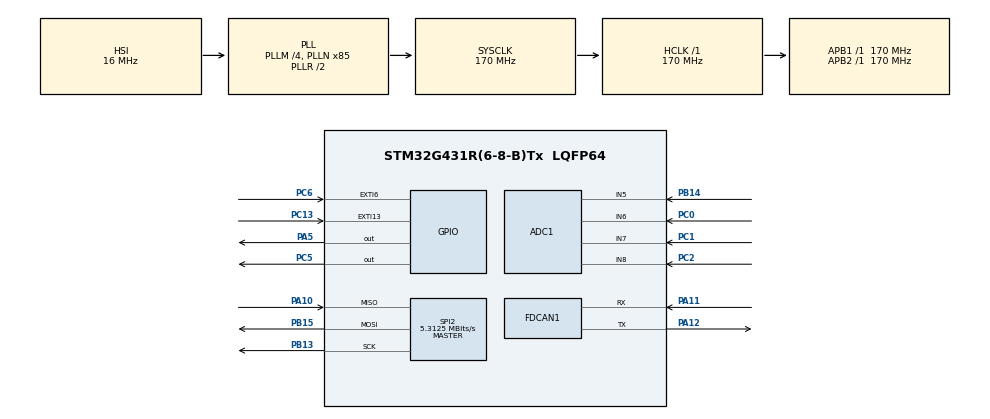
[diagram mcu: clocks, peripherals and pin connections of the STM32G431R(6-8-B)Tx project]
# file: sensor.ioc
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ADC1.Channel-1\#ChannelRegularConversion=ADC_CHANNEL_6
ADC1.Channel-6\#ChannelRegularConversion=ADC_CHANNEL_7
ADC1.Channel-7\#ChannelRegularConversion=ADC_CHANNEL_8
ADC1.Channel-8\#ChannelRegularConversion=ADC_CHANNEL_5
ADC1.ContinuousConvMode=DISABLE
ADC1.DMAContinuousRequests=DISABLE
ADC1.EnableInjectedConversion=DISABLE
ADC1.NbrOfConversion=4
ADC1.NbrOfConversionFlag=1
ADC1.OffsetNumber-1\#ChannelRegularConversion=ADC_OFFSET_NONE
ADC1.OffsetNumber-6\#ChannelRegularConversion=ADC_OFFSET_NONE
ADC1.OffsetNumber-7\#ChannelRegularConversion=ADC_OFFSET_NONE
ADC1.OffsetNumber-8\#ChannelRegularConversion=ADC_OFFSET_NONE
ADC1.Rank-1\#ChannelRegularConversion=1
ADC1.Rank-6\#ChannelRegularConversion=2
ADC1.Rank-7\#ChannelRegularConversion=3
ADC1.Rank-8\#ChannelRegularConversion=4
ADC1.SamplingTime-1\#ChannelRegularConversion=ADC_SAMPLETIME_92CYCLES_5
ADC1.SamplingTime-6\#ChannelRegularConversion=ADC_SAMPLETIME_92CYCLES_5
ADC1.SamplingTime-7\#ChannelRegularConversion=ADC_SAMPLETIME_92CYCLES_5
ADC1.SamplingTime-8\#ChannelRegularConversion=ADC_SAMPLETIME_92CYCLES_5
ADC1.master=1
Dma.ADC1.0.Direction=DMA_PERIPH_TO_MEMORY
Dma.ADC1.0.EventEnable=DISABLE
Dma.ADC1.0.Instance=DMA1_Channel1
Dma.ADC1.0.MemDataAlignment=DMA_MDATAALIGN_HALFWORD
Dma.ADC1.0.MemInc=DMA_MINC_ENABLE
Dma.ADC1.0.Mode=DMA_NORMAL
Dma.ADC1.0.PeriphDataAlignment=DMA_PDATAALIGN_HALFWORD
Dma.ADC1.0.PeriphInc=DMA_PINC_DISABLE
Dma.ADC1.0.Polarity=HAL_DMAMUX_REQ_GEN_RISING
Dma.ADC1.0.Priority=DMA_PRIORITY_LOW
Dma.ADC1.0.RequestNumber=1
Dma.ADC1.0.SignalID=NONE
Dma.ADC1.0.SyncEnable=DISABLE
Dma.ADC1.0.SyncPolarity=HAL_DMAMUX_SYNC_NO_EVENT
Dma.ADC1.0.SyncRequestNumber=1
Dma.ADC1.0.SyncSignalID=NONE
Dma.Request0=ADC1
FDCAN1.CalculateBaudRateNominal=499999
FDCAN1.CalculateTimeBitNominal=2000
FDCAN1.CalculateTimeQuantumNominal=117.64705882352942
FDCAN1.DataPrescaler=2
FDCAN1.DataTimeSeg1=14
FDCAN1.DataTimeSeg2=2
FDCAN1.Mode=FDCAN_MODE_NORMAL
FDCAN1.NominalPrescaler=20
FDCAN1.NominalTimeSeg1=14
FDCAN1.ProtocolException=ENABLE
FDCAN1.StdFiltersNbr=FDCAN_FILTER_COUNT
FDCAN1.TransmitPause=ENABLE
FREERTOS.Tasks01=defaultTask,24,128,StartDefaultTask,As weak,NULL,Dynamic,NULL,NULL;UsTask,40,128,StartUsTask,As weak,NULL,Dynamic,NULL,NULL;AdcTask,25,128,StartAdcTask,As weak,NULL,Dynamic,NULL,NULL;FdCanTask,40,128,StartFdCanTask,As weak,NULL,Dynamic,NULL,NULL
FREERTOS.configENABLE_BACKWARD_COMPATIBILITY=0
FREERTOS.configUSE_NEWLIB_REENTRANT=1
Mcu.Family=STM32G4
Mcu.Name=STM32G431R(6-8-B)Tx
Mcu.Package=LQFP64
NUCLEO-G431RB.BUTTON=1
NUCLEO-G431RB.LD1=true
NUCLEO-G431RB.VCP=true
NVIC.DMA1_Channel1_IRQn=true\:5\:0\:false\:false\:true\:true\:false\:true\:true
NVIC.EXTI15_10_IRQn=true\:5\:0\:false\:false\:true\:true\:false\:true\:true
NVIC.EXTI9_5_IRQn=true\:5\:0\:false\:false\:true\:true\:true\:true\:true
NVIC.FDCAN1_IT0_IRQn=true\:5\:0\:false\:false\:true\:true\:true\:true\:true
NVIC.FDCAN1_IT1_IRQn=true\:5\:0\:false\:false\:true\:true\:true\:true\:true
NVIC.PriorityGroup=NVIC_PRIORITYGROUP_4
NVIC.TIM4_IRQn=true\:5\:0\:false\:false\:true\:true\:true\:true\:true
NVIC.TIM6_DAC_IRQn=true\:15\:0\:false\:false\:true\:false\:false\:true\:true
NVIC.TimeBase=TIM6_DAC_IRQn
NVIC.TimeBaseIP=TIM6
PA10.Mode=Full_Duplex_Master
PA10.Signal=SPI2_MISO
PA11.Mode=FDCAN_Activate
PA11.Signal=FDCAN1_RX
PA12.Mode=FDCAN_Activate
PA12.Signal=FDCAN1_TX
PA13.GPIO_Label=T_SWDIO
PA13.Signal=SYS_JTMS-SWDIO
PA14.GPIO_Label=T_SWCLK
PA14.Signal=SYS_JTCK-SWCLK
PA2.Signal=LPUART1_TX
PA3.Signal=LPUART1_RX
PA5.Signal=GPIO_Output
PB11.Signal=ADC1_IN14
PB12.Signal=ADC1_IN11
PB13.Mode=Full_Duplex_Master
PB13.Signal=SPI2_SCK
PB14.Mode=IN5-Single-Ended
PB14.Signal=ADC1_IN5
PB15.Mode=Full_Duplex_Master
PB15.Signal=SPI2_MOSI
PB3.GPIO_Label=T_SWO
PB3.Signal=SYS_JTDO-SWO
PC0.Mode=IN6-Single-Ended
PC0.Signal=ADC1_IN6
PC1.Mode=IN7-Single-Ended
PC1.Signal=ADC1_IN7
PC13.Signal=GPXTI13
PC14-OSC32_IN.GPIO_Label=RCC_OSC32_OUT
PC14-OSC32_IN.Signal=RCC_OSC32_IN
PC15-OSC32_OUT.GPIO_Label=RCC_OSC32_OUT
PC15-OSC32_OUT.Signal=RCC_OSC32_OUT
PC2.Mode=IN8-Single-Ended
PC2.Signal=ADC1_IN8
PC5.Signal=GPIO_Output
PC6.GPIO_ModeDefaultEXTI=GPIO_MODE_IT_FALLING
PC6.Signal=GPXTI6
PF0-OSC_IN.GPIO_Label=RCC_OSC_IN
PF0-OSC_IN.Signal=RCC_OSC_IN
PF1-OSC_OUT.GPIO_Label=RCC_OSC_OUT
PF1-OSC_OUT.Signal=RCC_OSC_OUT
ProjectManager.HeapSize=0x200
ProjectManager.StackSize=0x400
ProjectManager.TargetToolchain=STM32CubeIDE
RCC.ADC12Freq_Value=170000000
RCC.AHBFreq_Value=170000000
RCC.APB1Freq_Value=170000000
RCC.APB1TimFreq_Value=170000000
RCC.APB2Freq_Value=170000000
RCC.APB2TimFreq_Value=170000000
RCC.CortexFreq_Value=170000000
RCC.EXTERNAL_CLOCK_VALUE=12288000
RCC.HCLKFreq_Value=170000000
RCC.HSE_VALUE=24000000
RCC.HSI48_VALUE=48000000
RCC.HSI_VALUE=16000000
RCC.LSE_VALUE=32768
RCC.PLLM=RCC_PLLM_DIV4
RCC.PLLN=85
RCC.RTCClockSelection=RCC_RTCCLKSOURCE_LSE
RCC.SYSCLKFreq_VALUE=170000000
RCC.SYSCLKSource=RCC_SYSCLKSOURCE_PLLCLK
RCC.USBFreq_Value=170000000
RCC.VCOOutputFreq_Value=340000000
SPI2.BaudRatePrescaler=SPI_BAUDRATEPRESCALER_32
SPI2.CalculateBaudRate=5.3125 MBits/s
SPI2.DataSize=SPI_DATASIZE_8BIT
SPI2.Direction=SPI_DIRECTION_2LINES
SPI2.Mode=SPI_MODE_MASTER
SPI2.VirtualType=VM_MASTER
STMicroelectronics.X-CUBE-ALGOBUILD.1.4.0.LibraryCcDSPOoLibraryJjDSPOoLibrary=true
TIM2.Channel-Output\ Compare1\ No\ Output=TIM_CHANNEL_1
TIM2.PeriodNoDither=TIM2_ARR
TIM2.Prescaler=TIM2_PSC
TIM4.AutoReloadPreload=TIM_AUTORELOAD_PRELOAD_DISABLE
TIM4.Channel-PWM\ Generation1\ No\ Output=TIM_CHANNEL_1
TIM4.PeriodNoDither=TIM4_ARR
TIM4.Prescaler=TIM4_PSC
TIM4.PulseNoDither_1=0
VP_FREERTOS_VS_CMSIS_V2.Mode=CMSIS_V2
VP_NUCLEO-G431RB_VS_BSP_COMMON.Mode=COMMON
VP_STMicroelectronics.X-CUBE-ALGOBUILD_VS_DSPOoLibraryJjLibrary_1.4.0_1.4.0.Mode=DSPOoLibraryJjLibrary
VP_SYS_VS_DBSignals.Mode=DisableDeadBatterySignals
VP_SYS_VS_tim6.Mode=TIM6
VP_TIM2_VS_no_output1.Mode=Output Compare1 No Output
VP_TIM4_VS_no_output1.Mode=PWM Generation1 No Output
board=NUCLEO-G431RB

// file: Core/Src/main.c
/* USER CODE BEGIN Header */
/**
  ******************************************************************************
  * @file           : main.c
  * @brief          : Main program body
  ******************************************************************************
  * @attention
  *
  * Copyright (c) 2025 STMicroelectronics.
  * All rights reserved.
  *
  * This software is licensed under terms that can be found in the LICENSE file
  * in the root directory of this software component.
  * If no LICENSE file comes with this software, it is provided AS-IS.
  *
  ******************************************************************************
  */
/* USER CODE END Header */
#include "main.h"
#include "cmsis_os.h"
#include "adc.h"
#include "dma.h"
#include "fdcan.h"
#include "spi.h"
#include "tim.h"
#include "gpio.h"

/* USER CODE BEGIN Includes */
#include "main/main.h"
/* USER CODE END Includes */

COM_InitTypeDef BspCOMInit;

void SystemClock_Config(void);
void MX_FREERTOS_Init(void);

int main(void)
{

  /* MCU Configuration--------------------------------------------------------*/

  /* Reset of all peripherals, Initializes the Flash interface and the Systick. */
  HAL_Init();

  /* Configure the system clock */
  SystemClock_Config();

  /* Initialize all configured peripherals */
  MX_GPIO_Init();
  MX_DMA_Init();
  MX_ADC1_Init();
  MX_FDCAN1_Init();
  MX_SPI2_Init();
  MX_TIM2_Init();
  MX_TIM4_Init();

  /* Init scheduler */
  osKernelInitialize();

  /* Call init function for freertos objects (in cmsis_os2.c) */
  MX_FREERTOS_Init();

  /* Initialize leds */
  BSP_LED_Init(LED_GREEN);

  /* Initialize USER push-button, will be used to trigger an interrupt each time it's pressed.*/
  BSP_PB_Init(BUTTON_USER, BUTTON_MODE_EXTI);

  /* Initialize COM1 port (115200, 8 bits (7-bit data + 1 stop bit), no parity */
  BspCOMInit.BaudRate   = 115200;
  BspCOMInit.WordLength = COM_WORDLENGTH_8B;
  BspCOMInit.StopBits   = COM_STOPBITS_1;
  BspCOMInit.Parity     = COM_PARITY_NONE;
  BspCOMInit.HwFlowCtl  = COM_HWCONTROL_NONE;
  if (BSP_COM_Init(COM1, &BspCOMInit) != BSP_ERROR_NONE)
  {
    Error_Handler();
  }

  /* Start scheduler */
  osKernelStart();

  /* We should never get here as control is now taken by the scheduler */

  /* Infinite loop */
  while (1)
  {

  }
}

void SystemClock_Config(void)
{
  RCC_OscInitTypeDef RCC_OscInitStruct = {0};
  RCC_ClkInitTypeDef RCC_ClkInitStruct = {0};

  /** Configure the main internal regulator output voltage
  */
  HAL_PWREx_ControlVoltageScaling(PWR_REGULATOR_VOLTAGE_SCALE1_BOOST);

  /** Initializes the RCC Oscillators according to the specified parameters
  * in the RCC_OscInitTypeDef structure.
  */
  RCC_OscInitStruct.OscillatorType = RCC_OSCILLATORTYPE_HSI;
  RCC_OscInitStruct.HSIState = RCC_HSI_ON;
  RCC_OscInitStruct.HSICalibrationValue = RCC_HSICALIBRATION_DEFAULT;
  RCC_OscInitStruct.PLL.PLLState = RCC_PLL_ON;
  RCC_OscInitStruct.PLL.PLLSource = RCC_PLLSOURCE_HSI;
  RCC_OscInitStruct.PLL.PLLM = RCC_PLLM_DIV4;
  RCC_OscInitStruct.PLL.PLLN = 85;
  RCC_OscInitStruct.PLL.PLLP = RCC_PLLP_DIV2;
  RCC_OscInitStruct.PLL.PLLQ = RCC_PLLQ_DIV2;
  RCC_OscInitStruct.PLL.PLLR = RCC_PLLR_DIV2;
  if (HAL_RCC_OscConfig(&RCC_OscInitStruct) != HAL_OK)
  {
    Error_Handler();
  }

  /** Initializes the CPU, AHB and APB buses clocks
  */
  RCC_ClkInitStruct.ClockType = RCC_CLOCKTYPE_HCLK|RCC_CLOCKTYPE_SYSCLK
                              |RCC_CLOCKTYPE_PCLK1|RCC_CLOCKTYPE_PCLK2;
  RCC_ClkInitStruct.SYSCLKSource = RCC_SYSCLKSOURCE_PLLCLK;
  RCC_ClkInitStruct.AHBCLKDivider = RCC_SYSCLK_DIV1;
  RCC_ClkInitStruct.APB1CLKDivider = RCC_HCLK_DIV1;
  RCC_ClkInitStruct.APB2CLKDivider = RCC_HCLK_DIV1;

  if (HAL_RCC_ClockConfig(&RCC_ClkInitStruct, FLASH_LATENCY_4) != HAL_OK)
  {
    Error_Handler();
  }
}

void HAL_TIM_PeriodElapsedCallback(TIM_HandleTypeDef *htim)
{
  /* USER CODE BEGIN Callback 0 */
  HAL_TIM_PeriodElapsedCallback_OWN(htim);
  /* USER CODE END Callback 0 */
  if (htim->Instance == TIM6) {
    HAL_IncTick();
  }
}

void Error_Handler(void)
{
  __disable_irq();
  while (1)
  {
  }
}

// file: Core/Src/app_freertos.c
/* USER CODE BEGIN Header */
/**
  ******************************************************************************
  * File Name          : app_freertos.c
  * Description        : Code for freertos applications
  ******************************************************************************
  * @attention
  *
  * Copyright (c) 2025 STMicroelectronics.
  * All rights reserved.
  *
  * This software is licensed under terms that can be found in the LICENSE file
  * in the root directory of this software component.
  * If no LICENSE file comes with this software, it is provided AS-IS.
  *
  ******************************************************************************
  */
/* USER CODE END Header */

#include "FreeRTOS.h"
#include "task.h"
#include "main.h"
#include "cmsis_os.h"

/* Definitions for defaultTask */
osThreadId_t defaultTaskHandle;
const osThreadAttr_t defaultTask_attributes = {
  .name = "defaultTask",
  .priority = (osPriority_t) osPriorityNormal,
  .stack_size = 128 * 4
};
/* Definitions for UsTask */
osThreadId_t UsTaskHandle;
const osThreadAttr_t UsTask_attributes = {
  .name = "UsTask",
  .priority = (osPriority_t) osPriorityHigh,
  .stack_size = 128 * 4
};
/* Definitions for AdcTask */
osThreadId_t AdcTaskHandle;
const osThreadAttr_t AdcTask_attributes = {
  .name = "AdcTask",
  .priority = (osPriority_t) osPriorityNormal1,
  .stack_size = 128 * 4
};
/* Definitions for FdCanTask */
osThreadId_t FdCanTaskHandle;
const osThreadAttr_t FdCanTask_attributes = {
  .name = "FdCanTask",
  .priority = (osPriority_t) osPriorityHigh,
  .stack_size = 128 * 4
};

void StartDefaultTask(void *argument);
void StartUsTask(void *argument);
void StartAdcTask(void *argument);
void StartFdCanTask(void *argument);

void MX_FREERTOS_Init(void); /* (MISRA C 2004 rule 8.1) */

void MX_FREERTOS_Init(void) {

  /* Create the thread(s) */
  /* creation of defaultTask */
  defaultTaskHandle = osThreadNew(StartDefaultTask, NULL, &defaultTask_attributes);

  /* creation of UsTask */
  UsTaskHandle = osThreadNew(StartUsTask, NULL, &UsTask_attributes);

  /* creation of AdcTask */
  AdcTaskHandle = osThreadNew(StartAdcTask, NULL, &AdcTask_attributes);

  /* creation of FdCanTask */
  FdCanTaskHandle = osThreadNew(StartFdCanTask, NULL, &FdCanTask_attributes);

}

__weak void StartDefaultTask(void *argument)
{
  for(;;)
  {
    osDelay(1);
  }
}

__weak void StartUsTask(void *argument)
{
  for(;;)
  {
    osDelay(1);
  }
}

__weak void StartAdcTask(void *argument)
{
  for(;;)
  {
    osDelay(1);
  }
}

__weak void StartFdCanTask(void *argument)
{
  for(;;)
  {
    osDelay(1);
  }
}
